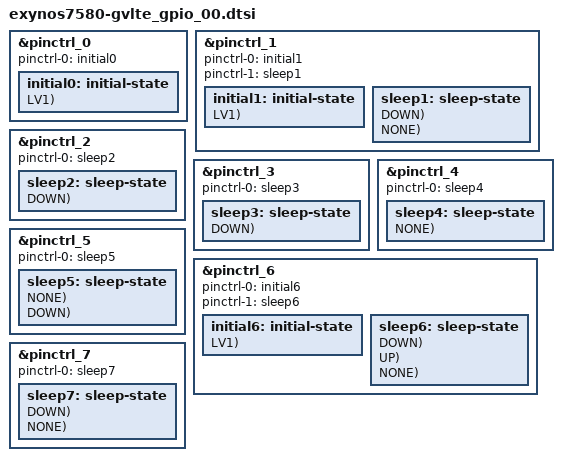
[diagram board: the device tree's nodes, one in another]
/*
 * Copyright (c) 2014 Samsung Electronics Co., Ltd.
 *		http://www.samsung.com
 *
 * This program is free software; you can redistribute it and/or modify
 * it under the terms of the GNU General Public License version 2 as
 * published by the Free Software Foundation.
*/

// Support GVLTE HW REV09 (b1001)

#include "exynos_gpio_config_macros.dtsi"

// 0x139B_0000(ALIVE): gpa0~3
&pinctrl_0 {
	pinctrl-names = "default";
	pinctrl-0 = <&initial0>;
	initial0: initial-state {
		PIN_IN(gpa2-5, DOWN, LV1);	/* NC */
	};
};

// 0x110B0000(AUD): gpz0 ~ gpz3
&pinctrl_1 {
	pinctrl-names = "default","sleep";
	pinctrl-0 = <&initial1>;
	pinctrl-1 = <&sleep1>;
	initial1: initial-state{
		PIN_IN(gpz3-0, DOWN, LV1);	/* NC */
		PIN_IN(gpz3-1, DOWN, LV1);	/* NC */
		PIN_IN(gpz3-2, DOWN, LV1);	/* NC */
		PIN_IN(gpz3-3, DOWN, LV1);	/* NC */
	};
	sleep1: sleep-state {
		PIN_SLP(gpz0-0, INPUT, DOWN);	/* BT_PCM_SYNC */
		PIN_SLP(gpz0-1, INPUT, DOWN);	/* BT_PCM_CLK */
		PIN_SLP(gpz0-2, INPUT, DOWN);	/* BT_PCM_RXD */
		PIN_SLP(gpz0-3, INPUT, DOWN);	/* BT_PCM_TXD */

		PIN_SLP(gpz1-0, OUT1, NONE);	/* BT_UART_TXD */
		PIN_SLP(gpz1-1, INPUT, NONE);	/* BT_UART_RXD */
		PIN_SLP(gpz1-2, INPUT, NONE);	/* BT_UART_CTS */
		PIN_SLP(gpz1-3, OUT1, NONE);	/* BT_UART_RTS */

		PIN_SLP(gpz2-0, INPUT, DOWN);	/* 2MIC_PCM_SYNC */
		PIN_SLP(gpz2-1, INPUT, DOWN);	/* 2MIC_PCM_CLK */
		PIN_SLP(gpz2-2, INPUT, DOWN);	/* 2MIC_AP_PCM_DI */
		PIN_SLP(gpz2-3, INPUT, DOWN);	/* 2MIC_AP_PCM_DO */

		PIN_SLP(gpz3-0, INPUT, DOWN);	/* NC */
		PIN_SLP(gpz3-1, INPUT, DOWN);	/* NC */
		PIN_SLP(gpz3-2, INPUT, DOWN);	/* NC */
		PIN_SLP(gpz3-3, INPUT, DOWN);	/* NC */
	};
};

// 0x138E0000(ESE): gpc0
&pinctrl_2 {
	pinctrl-names = "sleep";
	pinctrl-0 = <&sleep2>;
	sleep2: sleep-state {
		PIN_SLP(gpc0-0, INPUT, DOWN);	/* NC */
		PIN_SLP(gpc0-1, INPUT, DOWN);	/* NC */
		PIN_SLP(gpc0-2, INPUT, DOWN);	/* NC */
		PIN_SLP(gpc0-3, INPUT, DOWN);	/* NC */
	};
};

// 0x1375_0000(FSYS): gpr0~4
&pinctrl_3 {
	pinctrl-names = "sleep";
	pinctrl-0 = <&sleep3>;
	sleep3: sleep-state {
		PIN_SLP(gpr4-2, INPUT, DOWN);	/* NC */
	};
};

// 0x104E0000(MIF): gpm0
&pinctrl_4 {
	pinctrl-names = "sleep";
	pinctrl-0 = <&sleep4>;
	sleep4: sleep-state {
		PIN_SLP(gpm0-0, INPUT, NONE);	/* PMIC_SCL_1P8 */
		PIN_SLP(gpm0-1, INPUT, NONE);	/* PMIC_SDA_1P8 */
	};
};

// 0x138C0000(NFC): gpc3
&pinctrl_5 {
	pinctrl-names = "sleep";
	pinctrl-0 = <&sleep5>;
	sleep5: sleep-state {
		PIN_SLP(gpc3-0, INPUT, NONE);	/* GRIP_SDA_1P8 */
		PIN_SLP(gpc3-1, INPUT, NONE);	/* GRIP_SCL_1P8 */
		PIN_SLP(gpc3-2, INPUT, DOWN);	/* NC */
	};
};

// 0x139C0000(TOP): gpb0~2, gpc1~2, gpc5, gpd0~3, gpe0~1, gpf0~2, etc0
&pinctrl_6 {
	pinctrl-names = "default","sleep";
	pinctrl-0 = <&initial6>;
	pinctrl-1 = <&sleep6>;
	initial6: initial-state {
		PIN_IN(gpb0-2, DOWN, LV1);	/* NC */
		PIN_IN(gpb0-3, DOWN, LV1);	/* NC */

		PIN_IN(gpb1-0, DOWN, LV1);	/* NC */
		PIN_IN(gpb1-1, DOWN, LV1);	/* NC */

		PIN_IN(gpb2-4, DOWN, LV1);	/* NC */
		PIN_IN(gpb2-6, DOWN, LV1);	/* NC */
		PIN_IN(gpb2-7, DOWN, LV1);	/* NC */

		PIN_IN(gpd0-0, NONE, LV1);	/* HW_REV0 */
		PIN_IN(gpd0-1, NONE, LV1);	/* HW_REV1 */
		PIN_IN(gpd0-2, NONE, LV1);	/* HW_REV2 */
		PIN_IN(gpd0-3, NONE, LV1);	/* HW_REV3 */
		PIN_OUT_SET(gpd0-5, 0, LV1);    /* LDO26_EN */

		PIN_IN(gpd1-1, NONE, LV1);	/* LCD_ID */
		PIN_OUT_SET(gpd1-2, 1, LV1);    /* LCD_RESET */
		PIN_OUT_SET(gpd1-3, 1, LV1);    /* LVDS_RESET */
		PIN_OUT_SET(gpd1-4, 1, LV1);    /* BL_IC */
		PIN_OUT_SET(gpd1-6, 1, LV1);    /* LCD_EN */

		PIN_OUT_SET(gpd2-2, 1, LV1);	/* UART_CTL */

		PIN_IN(gpf1-4, DOWN, LV1);	/* NC */

		PIN_IN(gpc5-2, DOWN, LV1);	/* NC */
		PIN_IN(gpc5-3, DOWN, LV1);	/* NC */

		PIN_OUT_SET(gpe0-5, 1, LV1);    /* LVDS_EN */

		PIN_IN(gpd3-1, NONE, LV1);	/* UART_BOOT_ON */

		PIN_IN(gpf0-4, DOWN, LV1);	/* CPUAXI3 */

		PIN_IN(gpf2-0, DOWN, LV1);	/* NC */
		PIN_IN(gpf2-1, DOWN, LV1);	/* NC */
	};
	sleep6: sleep-state {
		PIN_SLP(gpb0-0, INPUT, DOWN);	/* AP_UART_RXD */
		PIN_SLP(gpb0-1, INPUT, DOWN);	/* AP_UART_TXD */
		PIN_SLP(gpb0-2, INPUT, DOWN);	/* NC */
		PIN_SLP(gpb0-3, INPUT, DOWN);	/* NC */
		PIN_SLP(gpb0-4, PREV, UP);	/* GPS_RXD */
		PIN_SLP(gpb0-5, PREV, UP);	/* GPS_TXD */
		PIN_SLP(gpb0-6, PREV, DOWN);	/* GPS_CTS */
		PIN_SLP(gpb0-7, PREV, DOWN);	/* GPS_RTS */

		PIN_SLP(gpb1-0, INPUT, DOWN);	/* NC */
		PIN_SLP(gpb1-1, INPUT, DOWN);	/* NC */

		PIN_SLP(gpb2-0, INPUT, DOWN);	/* NC */
		PIN_SLP(gpb2-1, INPUT, DOWN);	/* NC */
		PIN_SLP(gpb2-2, INPUT, DOWN);	/* NC */
		PIN_SLP(gpb2-3, INPUT, DOWN);	/* NC */
		PIN_SLP(gpb2-4, INPUT, DOWN);	/* NC */
		PIN_SLP(gpb2-5, INPUT, DOWN);	/* NC */
		PIN_SLP(gpb2-6, INPUT, DOWN);	/* NC */
		PIN_SLP(gpb2-7, INPUT, DOWN);	/* NC */

		PIN_SLP(gpc1-0, OUT1, NONE);	/* XBOOTLDO */
		PIN_SLP(gpc1-1, INPUT, DOWN);	/* NC */
		PIN_SLP(gpc1-2, INPUT, DOWN);	/* NC */
		PIN_SLP(gpc1-3, INPUT, DOWN);	/* NC */
		PIN_SLP(gpc1-4, INPUT, DOWN);	/* NC */

		PIN_SLP(gpc2-0, INPUT, NONE);	/* 2MIC_SDA_1P8 */
		PIN_SLP(gpc2-1, INPUT, NONE);	/* 2MIC_SCL_1P8 */
		PIN_SLP(gpc2-2, INPUT, NONE);	/* LVDS_SDA */
		PIN_SLP(gpc2-3, INPUT, NONE);	/* LVDS_SCL */
		PIN_SLP(gpc2-4, INPUT, NONE);	/* FG_SDA_1P8 */
		PIN_SLP(gpc2-5, INPUT, NONE);	/* FG_SCL_1P8 */

		PIN_SLP(gpc5-0, PREV, UP);	/* Don't use */
		PIN_SLP(gpc5-1, PREV, UP);	/* Don't use */
		PIN_SLP(gpc5-2, INPUT, DOWN);	/* NC */
		PIN_SLP(gpc5-3, INPUT, DOWN);	/* NC */

		PIN_SLP(gpd0-0, INPUT, NONE);	/* HW_REV0 */
		PIN_SLP(gpd0-1, INPUT, NONE);	/* HW_REV1 */
		PIN_SLP(gpd0-2, INPUT, NONE);	/* HW_REV2 */
		PIN_SLP(gpd0-3, INPUT, NONE);	/* HW_REV3 */
		PIN_SLP(gpd0-4, PREV, NONE);	/* DS_DET */
		PIN_SLP(gpd0-5, OUT0, DOWN);	/* LDO26_EN */
		PIN_SLP(gpd0-6, INPUT, DOWN);	/* CAM_SENSOR_CORE_EN */
		PIN_SLP(gpd0-7, INPUT, DOWN);	/* TE */

		PIN_SLP(gpd1-0, PREV, NONE);	/* WLAN_PDn */
		PIN_SLP(gpd1-1, INPUT, NONE);	/* LCD_ID */
		PIN_SLP(gpd1-2, OUT0, DOWN);	/* LCD_REST */
		PIN_SLP(gpd1-3, OUT0, DOWN);	/* MLCD_RST:LVDS */
		PIN_SLP(gpd1-4, OUT0, DOWN);	/* BL_ON */
		PIN_SLP(gpd1-5, OUT0, DOWN);	/* OTG_EN */
		PIN_SLP(gpd1-6, OUT0, DOWN);	/* LCD_EN */

		PIN_SLP(gpd2-0, INPUT, NONE);	/* BL1_SCL_1P8 */
		PIN_SLP(gpd2-1, INPUT, NONE);	/* BL1_SDA_1P8 */
		PIN_SLP(gpd2-2, PREV, NONE);	/* UART_CTL */
		PIN_SLP(gpd2-3, INPUT, DOWN);	/* TSP_RST */
		PIN_SLP(gpd2-4, INPUT, NONE);	/* BL2_SCL */
		PIN_SLP(gpd2-5, INPUT, NONE);	/* BL2_SDA */
		PIN_SLP(gpd2-6, OUT0, DOWN);	/* GPS_EN */
		PIN_SLP(gpd2-7, PREV, NONE);	/* BTP_OCP_EN */

		PIN_SLP(gpd3-0, INPUT, DOWN);	/* NC */
		PIN_SLP(gpd3-1, INPUT, NONE);	/* UART_BOOT_ON */
		PIN_SLP(gpd3-2, INPUT, DOWN);	/* BTP_1V8_EN */
		PIN_SLP(gpd3-3, INPUT, NONE);	/* MUIC_SCL_1P8 */
		PIN_SLP(gpd3-4, INPUT, NONE);	/* MUIC_SDA_1P8 */

		PIN_SLP(gpe0-0, INPUT, DOWN);	/* NC */
		PIN_SLP(gpe0-1, INPUT, DOWN);	/* NC */
		PIN_SLP(gpe0-2, INPUT, DOWN);	/* NC */
		PIN_SLP(gpe0-3, INPUT, DOWN);	/* VTCAM_RST_N */
		PIN_SLP(gpe0-4, INPUT, DOWN);	/* CAM_RST */
		PIN_SLP(gpe0-5, OUT0, DOWN);	/* LVDS_EN */
		PIN_SLP(gpe0-6, PREV, NONE);	/* CP_RST_N */
		PIN_SLP(gpe0-7, INPUT, DOWN);	/* NC */

		PIN_SLP(gpe1-0, PREV, NONE);	/* PM_WRSTBI */
		PIN_SLP(gpe1-1, INPUT, DOWN);	/* NC */
		PIN_SLP(gpe1-2, INPUT, DOWN);	/* NC */
		PIN_SLP(gpe1-3, INPUT, DOWN);	/* NC */
		PIN_SLP(gpe1-4, INPUT, DOWN);	/* NC */

		PIN_SLP(gpf0-0, INPUT, NONE);	/* WIFI_GRIP_SDA_1P8 */
		PIN_SLP(gpf0-1, INPUT, NONE);	/* WIFI_GRIP_SCL_1P8 */
		PIN_SLP(gpf0-2, INPUT, DOWN);	/* VTCAM_SDA_1P8 */
		PIN_SLP(gpf0-3, INPUT, DOWN);	/* VTCAM_SCL_1P8 */
		PIN_SLP(gpf0-4, INPUT, DOWN);	/* CPUAXI3 */

		PIN_SLP(gpf1-0, INPUT, DOWN);	/* NC */
		PIN_SLP(gpf1-1, INPUT, DOWN);	/* NC */
		PIN_SLP(gpf1-2, INPUT, DOWN);	/* NC */
		PIN_SLP(gpf1-3, INPUT, DOWN);	/* NC */
		PIN_SLP(gpf1-4, INPUT, DOWN);	/* NC */
		PIN_SLP(gpf1-5, INPUT, DOWN);	/* NC */
		PIN_SLP(gpf1-6, INPUT, DOWN);	/* NC */
		PIN_SLP(gpf1-7, INPUT, DOWN);	/* NC */

		PIN_SLP(gpf2-0, INPUT, DOWN);	/* NC */
		PIN_SLP(gpf2-1, INPUT, DOWN);	/* NC */
	};
};

// 0x138D0000(TOUCH): gpc4
&pinctrl_7 {
	pinctrl-names = "sleep";
	pinctrl-0= <&sleep7>;
	sleep7: sleep-state {
		PIN_SLP(gpc4-0, INPUT, DOWN);	/* TSP_SDA_1P8 */
		PIN_SLP(gpc4-1, INPUT, DOWN);	/* TSP_SCL_1P8 */
		PIN_SLP(gpc4-2, PREV, NONE);	/* BT_EN */
	};
};

